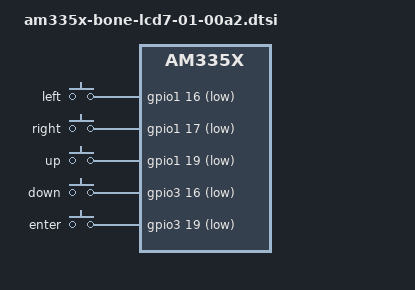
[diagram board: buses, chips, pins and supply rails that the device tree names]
/*
 * Copyright (C) 2012 Texas Instruments Incorporated - http://www.ti.com/
 *
 * This program is free software; you can redistribute it and/or modify
 * it under the terms of the GNU General Public License version 2 as
 * published by the Free Software Foundation.
 */

/ {
	gpio_keys {
		compatible = "gpio-keys";
		pinctrl-names = "default";
		pinctrl-0 = <&lcd7_01_00a2_keymap_pins>;

		#address-cells = <1>;
		#size-cells = <0>;

		button@1 {
			debounce_interval = <50>;
			linux,code = <105>;
			label = "left";
			gpios = <&gpio1 16 0x1>;
			gpio-key,wakeup;
			autorepeat;
		};
		button@2 {
			debounce_interval = <50>;
			linux,code = <106>;
			label = "right";
			gpios = <&gpio1 17 0x1>;
			gpio-key,wakeup;
			autorepeat;
		};
		button@3 {
			debounce_interval = <50>;
			linux,code = <103>;
			label = "up";
			gpios = <&gpio1 19 0x1>;
			gpio-key,wakeup;
			autorepeat;
		};
		button@4 {
			debounce_interval = <50>;
			linux,code = <108>;
			label = "down";
			gpios = <&gpio3 16 0x1>;
			gpio-key,wakeup;
			autorepeat;
		};
		button@5 {
			debounce_interval = <50>;
			linux,code = <28>;
			label = "enter";
			gpios = <&gpio3 19 0x1>;
			gpio-key,wakeup;
		};
	};
};

#include "am335x-bone-lcd-led-gpio1-28.dtsi"
#include "am335x-bone-lcd-gpio-backlight-gpio1-18.dtsi"
#include "am335x-bone-ti-tscadc-4-wire.dtsi"
#include "am335x-bone-lcd7.dtsi"
